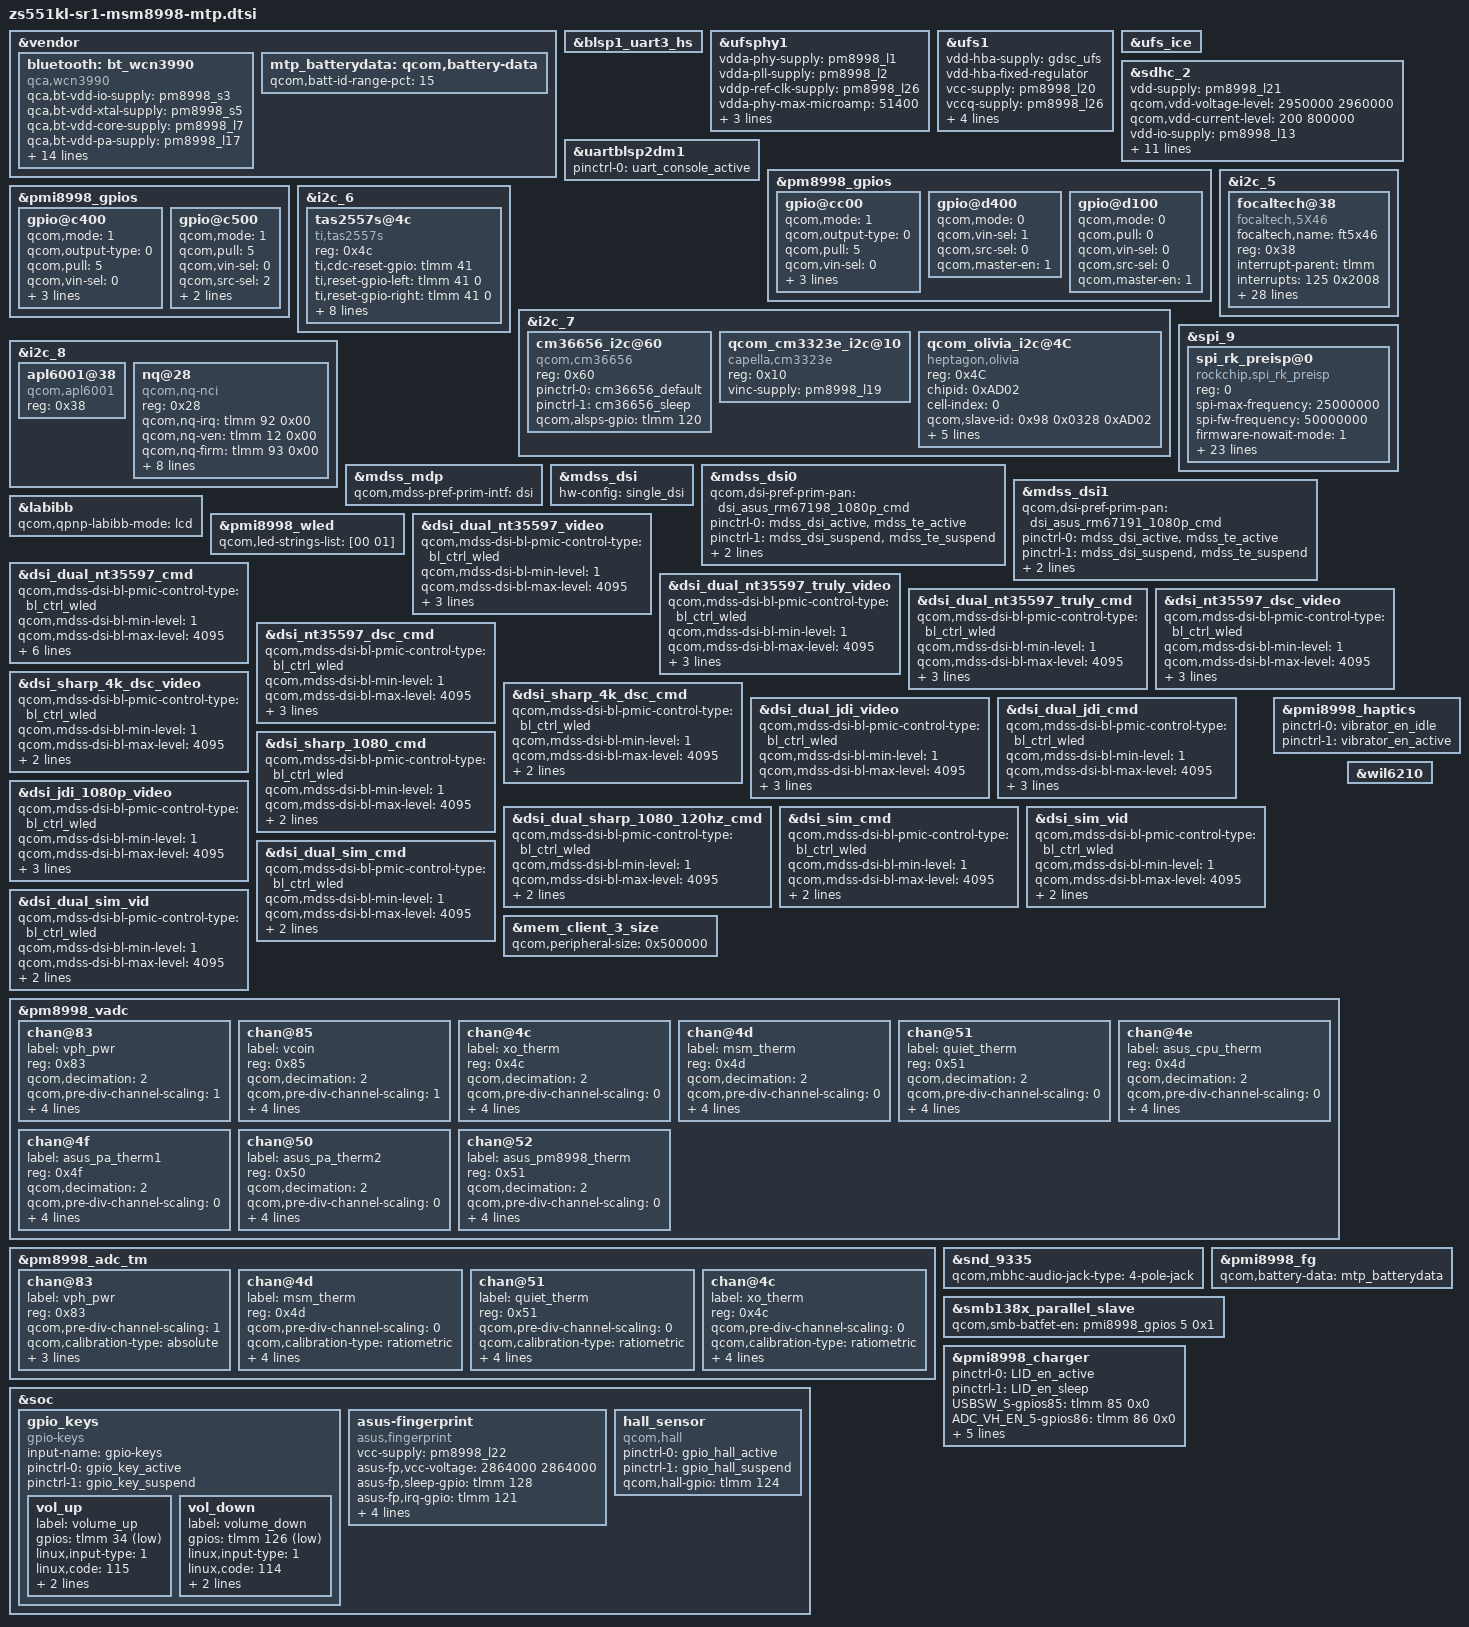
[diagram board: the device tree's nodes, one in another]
/* Copyright (c) 2016-2017, The Linux Foundation. All rights reserved.
 *
 * This program is free software; you can redistribute it and/or modify
 * it under the terms of the GNU General Public License version 2 and
 * only version 2 as published by the Free Software Foundation.
 *
 * This program is distributed in the hope that it will be useful,
 * but WITHOUT ANY WARRANTY; without even the implied warranty of
 * MERCHANTABILITY or FITNESS FOR A PARTICULAR PURPOSE.  See the
 * GNU General Public License for more details.
 */

#include <dt-bindings/interrupt-controller/irq.h>
#include "zs551kl-sr1-msm8998-pinctrl.dtsi"
#include "zs551kl-sr1-msm8998-camera-sensor-mtp.dtsi"
&vendor {
	bluetooth: bt_wcn3990 {
		compatible = "qca,wcn3990";
		qca,bt-vdd-io-supply = <&pm8998_s3>;
		qca,bt-vdd-xtal-supply = <&pm8998_s5>;
		qca,bt-vdd-core-supply = <&pm8998_l7>;
		qca,bt-vdd-pa-supply = <&pm8998_l17>;
		qca,bt-vdd-ldo-supply = <&pm8998_l25>;
		qca,bt-chip-pwd-supply = <&pmi8998_bob_pin1>;
		clocks = <&clock_gcc clk_rf_clk2_pin>;
		clock-names = "rf_clk2";

		qca,bt-vdd-io-voltage-level = <1352000 1352000>;
		qca,bt-vdd-xtal-voltage-level = <2040000 2040000>;
		qca,bt-vdd-core-voltage-level = <1800000 1800000>;
		qca,bt-vdd-pa-voltage-level = <1304000 1304000>;
		qca,bt-vdd-ldo-voltage-level = <3312000 3312000>;
		qca,bt-chip-pwd-voltage-level = <3600000 3600000>;

		qca,bt-vdd-io-current-level = <1>; /* LPM/PFM */
		qca,bt-vdd-xtal-current-level = <1>; /* LPM/PFM */
		qca,bt-vdd-core-current-level = <1>; /* LPM/PFM */
		qca,bt-vdd-pa-current-level = <1>; /* LPM/PFM */
		qca,bt-vdd-ldo-current-level = <1>; /* LPM/PFM */
	};
};

&blsp1_uart3_hs {
	status = "ok";
};

&ufsphy1 {
	vdda-phy-supply = <&pm8998_l1>;
	vdda-pll-supply = <&pm8998_l2>;
	vddp-ref-clk-supply = <&pm8998_l26>;
	vdda-phy-max-microamp = <51400>;
	vdda-pll-max-microamp = <14600>;
	vddp-ref-clk-max-microamp = <100>;
	vddp-ref-clk-always-on;
	status = "ok";
};

&ufs1 {
	vdd-hba-supply = <&gdsc_ufs>;
	vdd-hba-fixed-regulator;
	vcc-supply = <&pm8998_l20>;
	vccq-supply = <&pm8998_l26>;
	vccq2-supply = <&pm8998_s4>;
	vcc-max-microamp = <750000>;
	vccq-max-microamp = <560000>;
	vccq2-max-microamp = <750000>;
	status = "ok";
};

&ufs_ice {
	status = "ok";
};

&sdhc_2 {
	vdd-supply = <&pm8998_l21>;
	qcom,vdd-voltage-level = <2950000 2960000>;
	qcom,vdd-current-level = <200 800000>;

	vdd-io-supply = <&pm8998_l13>;
	qcom,vdd-io-voltage-level = <1808000 2960000>;
	qcom,vdd-io-current-level = <200 22000>;

	pinctrl-names = "active", "sleep";
	pinctrl-0 = <&sdc2_clk_on  &sdc2_cmd_on &sdc2_data_on &sdc2_cd_on>;
	pinctrl-1 = <&sdc2_clk_off &sdc2_cmd_off &sdc2_data_off &sdc2_cd_off>;

	qcom,clk-rates = <400000 20000000 25000000
				50000000 100000000 200000000>;
	qcom,bus-speed-mode = "SDR12", "SDR25", "SDR50", "DDR50", "SDR104";

	cd-gpios = <&tlmm 95 0x0>;

	status = "ok";
};

&uartblsp2dm1 {
	status = "ok";
	pinctrl-names = "default";
	pinctrl-0 = <&uart_console_active>;
};

&pm8998_gpios {
	/* GPIO 2 for Home Key */
	/*
	gpio@c100 {
		status = "okay";
		qcom,mode = <0>;
		qcom,pull = <0>;
		qcom,vin-sel = <0>;
		qcom,src-sel = <0>;
		qcom,out-strength = <1>;
	};
	*/
	/* GPIO 6 for Vol+ Key */
	/*
	gpio@c500 {
		status = "okay";
		qcom,mode = <0>;
		qcom,pull = <0>;
		qcom,vin-sel = <0>;
		qcom,src-sel = <0>;
		qcom,out-strength = <1>;
	};
	*/
	/* GPIO 7 for Snapshot Key */
	/*
	gpio@c600 {
		status = "okay";
		qcom,mode = <0>;
		qcom,pull = <0>;
		qcom,vin-sel = <0>;
		qcom,src-sel = <0>;
		qcom,out-strength = <1>;
	};
	*/
	/* GPIO 8 for Focus Key */
	/*
	gpio@c700 {
		status = "okay";
		qcom,mode = <0>;
		qcom,pull = <0>;
		qcom,vin-sel = <0>;
		qcom,src-sel = <0>;
		qcom,out-strength = <1>;
	};
	*/
	gpio@cc00 { /* GPIO 13 */
		qcom,mode = <1>;
		qcom,output-type = <0>;
		qcom,pull = <5>;
		qcom,vin-sel = <0>;
		qcom,out-strength = <1>;
		qcom,src-sel = <3>;
		qcom,master-en = <1>;
		status = "okay";
	};

	/* GPIO 21 (NFC_CLK_REQ) */
	gpio@d400 {
		qcom,mode = <0>;
		qcom,vin-sel = <1>;
		qcom,src-sel = <0>;
		qcom,master-en = <1>;
		status = "okay";
	};

	/* GPIO 18 SMB138X */
	gpio@d100 {
		qcom,mode = <0>;
		qcom,pull = <0>;
		qcom,vin-sel = <0>;
		qcom,src-sel = <0>;
		qcom,master-en = <1>;
		status = "okay";
	};
};

&pmi8998_gpios {
	/* GPIO 5 for SMB138x BATFET_EN signal */
	gpio@c400 {
		qcom,mode = <1>;
		qcom,output-type = <0>;
		qcom,pull = <5>;
		qcom,vin-sel = <0>;
		qcom,out-strength = <1>;
		qcom,src-sel = <3>;
		qcom,master-en = <1>;
		status = "okay";
	};

	/* GPIO 6 for the internal QNOVO discharge FET control signal */
	gpio@c500 {
		status = "okay";
		qcom,mode = <1>;
		qcom,pull = <5>;
		qcom,vin-sel = <0>;
		qcom,src-sel = <2>;
		qcom,out-strength = <1>;
		qcom,master-en = <1>;
	};
};

//+++.....................................................Peripheral bus part....................................................+++//
 
&i2c_5 {	/* BLSP5 (BLSP QUP5) for Touch */
	status = "okay";
	focaltech@38 {
		compatible = "focaltech,5X46";
		focaltech,name = "ft5x46";
		reg = <0x38>;
		interrupt-parent = <&tlmm>;
		interrupts = <125 0x2008>;
		vdd-supply = <&pm8998_l28>;
		vcc_i2c-supply = <&pm8998_l14>;
		/* pins used by touchscreen */
		/*pinctrl-names = "pmx_ts_active","pmx_ts_suspend","pmx_ts_release";
		pinctrl-0 = <&ts_int_active &ts_reset_active>;
		pinctrl-1 = <&ts_int_suspend &ts_reset_suspend>;
		pinctrl-2 = <&ts_release>;*/
		focaltech,family-id = <0x36>;
		focaltech,reset-gpio = <&tlmm 89 0x0>;
		focaltech,irq-gpio = <&tlmm 125 0x2008>;
		/*focaltech,tpid1-gpio=<&tlmm 140 0x0>;
		focaltech,tpid0-gpio=<&tlmm 67 0x0>;*/
		/*focaltech,lcdid0-gpio=<&tlmm 59 0x0>;
		focaltech,lcdid1-gpio=<&tlmm 62 0x0>;*/
		focaltech,display-coords = <0 0 1080 1920>;
		focaltech,panel-coords = <0 0 1080 1920>;
		focaltech,button-map= <139 102 158>;
		focaltech,have-key;
		focaltech,key-number = <3>;
		focaltech,max-touch-number = <10>;
		focaltech,keys = <158 102 139>;
		focaltech,key-y-coord = <2000>;
		focaltech,key-x-coord = <200 400 600>;

		focaltech,no-force-update;
		focaltech,i2c-pull-up;
		focaltech,group-id = <1>;
		focaltech,hard-reset-delay-ms = <20>;
		focaltech,soft-reset-delay-ms = <200>;
		focaltech,num-max-touches = <5>;
		focaltech,fw-delay-aa-ms = <30>;
		focaltech,fw-delay-55-ms = <30>;
		focaltech,fw-upgrade-id1 = <0x79>;
		focaltech,fw-upgrade-id2 = <0x18>;
		focaltech,fw-delay-readid-ms = <10>;
		focaltech,fw-delay-era-flsh-ms = <2000>;
		focaltech,fw-auto-cal;
		focaltech,ignore-id-check;

	};
};

&i2c_6 {	/* BLSP6 (BLSP QUP6) for Audio */
	status = "okay";
	tas2557s@4c {
		compatible = "ti,tas2557s";
		reg = <0x4c>;
		ti,cdc-reset-gpio = <&tlmm 41 0>;
		ti,reset-gpio-left = <&tlmm 41 0>;
		ti,reset-gpio-right = <&tlmm 41 0>;
		ti,load = <0>;   /* 0, 8Ohm; 1, 6Ohm; 2, 4Ohm */
		ti,irq-gpio-left = <&tlmm 76 0>;
		ti,irq-gpio-right = <&tlmm 75 0>;
		ti,left-channel = <0x4d>;
		ti,right-channel = <0x4c>;
		ti,echo-ref = <0>;   /* 0, left channel; 1, right channel; 2, both */
		ti,i2s-bits = <24>;  /* support 16, 24, 32 */
		ti,bypass-tmax = <0>;   /* 0, not bypass; 1, bypass */
	};
};

&i2c_7 {	/* BLSP7 (BLSP QUP7) for Sensors */
	status = "okay";

	/* ASUS_BSP +++ ShawnHuang CM36656 */
	cm36656_i2c@60 {
		compatible = "qcom,cm36656";
		reg = <0x60>;
		pinctrl-names = "alsps_gpio_high","alsps_gpio_low";
		pinctrl-0 = <&cm36656_default>;
		pinctrl-1 = <&cm36656_sleep>;
		qcom,alsps-gpio = <&tlmm 120 0x0>;
	};
	/* ASUS_BSP --- ShawnHuang CM36656 */

	/* ASUS_BSP: Vincent: rgb sensor i2c ++*/
	qcom_cm3323e_i2c@10 {
		compatible = "capella,cm3323e";
		reg = <0x10>;
		vinc-supply=<&pm8998_l19>;
	};		
	/* ASUS_BSP: Vincent: rgb sensor i2c --*/

	/* ASUS_BSP: Vincent: Laser sensor i2c ++*/
	qcom_olivia_i2c@4C {
		compatible = "heptagon,olivia";
		reg = <0x4C>;		
		chipid = <0xAD02>;
		cell-index = <0>;
		qcom,slave-id = <0x98 0x0328 0xAD02>;
		label = "Olivia";
		vinc-supply=<&pm8998_l19>;
		qcom,elisa-gpio = <&tlmm 117 0x0>;
		pinctrl-names = "laser_gpio_high","laser_gpio_low";
		pinctrl-0 = <&laser_default>;
		pinctrl-1 = <&laser_sleep>;		
	};
	/* ASUS_BSP: Vincent: Laser sensor i2c --*/	
};

&i2c_8 {	/* BLSP8(BLSP2 QUP2) for Audio, Buttery, Power */
	status = "okay";

	apl6001@38 {
		compatible = "qcom,apl6001";
		reg = <0x38>;
		#address-cells = <1>;
		#size-cells = <0>;
	};

	nq@28 {
		compatible = "qcom,nq-nci";
		reg = <0x28>;
		qcom,nq-irq = <&tlmm 92 0x00>;
		qcom,nq-ven = <&tlmm 12 0x00>;
		qcom,nq-firm = <&tlmm 93 0x00>;
		qcom,nq-clkreq = <&pm8998_gpios 21 0x00>;
		qcom,nq-esepwr = <&tlmm 116 0x00>;
		interrupt-parent = <&tlmm>;
		qcom,clk-src = "BBCLK3";
		interrupts = <92 0>;
		interrupt-names = "nfc_irq";
		pinctrl-names = "nfc_active", "nfc_suspend";
		pinctrl-0 = <&nfc_int_active &nfc_enable_active>;
		pinctrl-1 = <&nfc_int_suspend &nfc_enable_suspend>;
		clocks = <&clock_gcc clk_ln_bb_clk3_pin>;
		clock-names = "ref_clk";
	};

};

// ASUS_BSP Deka +++ "Bring up Pre-ISP RK1608"
&spi_9 {	/* BLSP9 (BLSP QUP9) for SPI RK1608 */
	status = "okay";
	spi_rk_preisp@0 {
		compatible =  "rockchip,spi_rk_preisp";
		reg = <0>;
		spi-max-frequency = <25000000>;
		spi-fw-frequency = <50000000>; /* 2 times spi-max-frequency*/
		firmware-nowait-mode = <1>;
		irq-gpio = <&tlmm 9 0>;
		reset-gpio = <&tlmm 23 0>;
		sleepst-gpio=<&tlmm 26 0>;
		wakeup-gpio = <&tlmm 8 0>;
		snapshot-gpio=<&tlmm 100 0>;
		en1v0-gpio = <&pm8998_gpios 20 0>;
		core_vdd-supply=<&pm8998_lvs1>;
		qcom,cam-vreg-name = "core_vdd";
		qcom,cam-vreg-min-voltage = <0>;
		qcom,cam-vreg-max-voltage = <0>;
		qcom,cam-vreg-op-mode = <0>;
		pinctrl-names = "cam_default", "cam_suspend";
		pinctrl-0 = <&preisp_mclk_default &preisp_irq_gpios_default &preisp_gpios_default>;
		pinctrl-1 = <&preisp_mclk_sleep &preisp_irq_gpios_sleep &preisp_gpios_sleep>;
		gpios=<&tlmm 16 0>;
		qcom,gpio-req-tbl-num = <0 >;
		qcom,gpio-req-tbl-flags = <1 >;
		qcom,gpio-req-tbl-label = "CAMIF_MCLK3";
		clocks = <&clock_mmss clk_mclk3_clk_src>,<&clock_mmss clk_mmss_camss_mclk3_clk>;
		clock-names = "cam_src_clk", "cam_clk";
		qcom,clock-rates = <19200000 0>;
	};
};
// ASUS_BSP Deka --- "Bring up Pre-ISP RK1608"


//---.....................................................Peripheral bus part....................................................---//
// ASUS_BSP Remove HDMI HDP +++
/*

&mdss_hdmi_tx {
	pinctrl-names = "hdmi_hpd_active", "hdmi_ddc_active", "hdmi_cec_active",
				"hdmi_active", "hdmi_sleep";
	pinctrl-0 = <&mdss_hdmi_5v_active  &mdss_hdmi_hpd_active
			&mdss_hdmi_ddc_suspend &mdss_hdmi_cec_suspend>;
	pinctrl-1 = <&mdss_hdmi_5v_active &mdss_hdmi_hpd_active
			&mdss_hdmi_ddc_active &mdss_hdmi_cec_suspend>;
	pinctrl-2 = <&mdss_hdmi_5v_active &mdss_hdmi_hpd_active
			&mdss_hdmi_cec_active &mdss_hdmi_ddc_suspend>;
	pinctrl-3 = <&mdss_hdmi_5v_active &mdss_hdmi_hpd_active
			&mdss_hdmi_ddc_active &mdss_hdmi_cec_active>;
	pinctrl-4 = <&mdss_hdmi_5v_suspend &mdss_hdmi_hpd_suspend
			&mdss_hdmi_ddc_suspend &mdss_hdmi_cec_suspend>;
};
*/
// ASUS_BSP Remove HDMI HDP ---

// ASUS BSP Display, disable DP +++
/*
&mdss_dp_ctrl {
	pinctrl-names = "mdss_dp_active", "mdss_dp_sleep";
	pinctrl-0 = <&mdss_dp_aux_active &mdss_dp_usbplug_cc_active>;
	pinctrl-1 = <&mdss_dp_aux_suspend &mdss_dp_usbplug_cc_suspend>;
	qcom,aux-en-gpio = <&tlmm 77 0>;
	qcom,aux-sel-gpio = <&tlmm 78 0>;
	qcom,usbplug-cc-gpio = <&tlmm 38 0>;
};
*/
// ASUS BSP Display, disable DP ---

&mdss_mdp {
	qcom,mdss-pref-prim-intf = "dsi";
};

&mdss_dsi {
	hw-config = "single_dsi";
};

&mdss_dsi0 {
	qcom,dsi-pref-prim-pan = <&dsi_asus_rm67198_1080p_cmd>;
	pinctrl-names = "mdss_default", "mdss_sleep";
	pinctrl-0 = <&mdss_dsi_active &mdss_te_active>;
	pinctrl-1 = <&mdss_dsi_suspend &mdss_te_suspend>;
	qcom,platform-reset-gpio = <&tlmm 94 0>;
	qcom,platform-te-gpio = <&tlmm 10 0>;
};

&mdss_dsi1 {
	qcom,dsi-pref-prim-pan = <&dsi_asus_rm67191_1080p_cmd>;
	pinctrl-names = "mdss_default", "mdss_sleep";
	pinctrl-0 = <&mdss_dsi_active &mdss_te_active>;
	pinctrl-1 = <&mdss_dsi_suspend &mdss_te_suspend>;
	qcom,platform-reset-gpio = <&tlmm 94 0>;
	qcom,platform-te-gpio = <&tlmm 10 0>;
};

&labibb {
	status = "ok";
	qcom,qpnp-labibb-mode = "lcd";
};

&pmi8998_wled {
	qcom,led-strings-list = [00 01];
};

&dsi_dual_nt35597_video {
	qcom,mdss-dsi-bl-pmic-control-type = "bl_ctrl_wled";
	qcom,mdss-dsi-bl-min-level = <1>;
	qcom,mdss-dsi-bl-max-level = <4095>;
	qcom,mdss-dsi-mode-sel-gpio-state = "dual_port";
	qcom,panel-supply-entries = <&dsi_panel_pwr_supply>;
};

&dsi_dual_nt35597_cmd {
	qcom,mdss-dsi-bl-pmic-control-type = "bl_ctrl_wled";
	qcom,mdss-dsi-bl-min-level = <1>;
	qcom,mdss-dsi-bl-max-level = <4095>;
	qcom,mdss-dsi-mode-sel-gpio-state = "dual_port";
	qcom,panel-supply-entries = <&dsi_panel_pwr_supply>;
	qcom,partial-update-enabled = "single_roi";
	qcom,panel-roi-alignment = <720 256 720 256 1440 256>;
};

&dsi_dual_nt35597_truly_video {
	qcom,mdss-dsi-bl-pmic-control-type = "bl_ctrl_wled";
	qcom,mdss-dsi-bl-min-level = <1>;
	qcom,mdss-dsi-bl-max-level = <4095>;
	qcom,mdss-dsi-mode-sel-gpio-state = "dual_port";
	qcom,panel-supply-entries = <&dsi_panel_pwr_supply>;
};

&dsi_dual_nt35597_truly_cmd {
	qcom,mdss-dsi-bl-pmic-control-type = "bl_ctrl_wled";
	qcom,mdss-dsi-bl-min-level = <1>;
	qcom,mdss-dsi-bl-max-level = <4095>;
	qcom,mdss-dsi-mode-sel-gpio-state = "dual_port";
	qcom,panel-supply-entries = <&dsi_panel_pwr_supply>;
};

&dsi_nt35597_dsc_video {
	qcom,mdss-dsi-bl-pmic-control-type = "bl_ctrl_wled";
	qcom,mdss-dsi-bl-min-level = <1>;
	qcom,mdss-dsi-bl-max-level = <4095>;
	qcom,mdss-dsi-mode-sel-gpio-state = "single_port";
	qcom,panel-supply-entries = <&dsi_panel_pwr_supply>;
};

&dsi_nt35597_dsc_cmd {
	qcom,mdss-dsi-bl-pmic-control-type = "bl_ctrl_wled";
	qcom,mdss-dsi-bl-min-level = <1>;
	qcom,mdss-dsi-bl-max-level = <4095>;
	qcom,mdss-dsi-mode-sel-gpio-state = "single_port";
	qcom,panel-supply-entries = <&dsi_panel_pwr_supply>;
};

&dsi_sharp_4k_dsc_video {
	qcom,mdss-dsi-bl-pmic-control-type = "bl_ctrl_wled";
	qcom,mdss-dsi-bl-min-level = <1>;
	qcom,mdss-dsi-bl-max-level = <4095>;
	qcom,panel-supply-entries = <&dsi_panel_pwr_supply>;
};

&dsi_sharp_4k_dsc_cmd {
	qcom,mdss-dsi-bl-pmic-control-type = "bl_ctrl_wled";
	qcom,mdss-dsi-bl-min-level = <1>;
	qcom,mdss-dsi-bl-max-level = <4095>;
	qcom,panel-supply-entries = <&dsi_panel_pwr_supply>;
};

&dsi_dual_jdi_video {
	qcom,mdss-dsi-bl-pmic-control-type = "bl_ctrl_wled";
	qcom,mdss-dsi-bl-min-level = <1>;
	qcom,mdss-dsi-bl-max-level = <4095>;
	qcom,5v-boost-gpio = <&tlmm 51 0>;
	qcom,panel-supply-entries = <&dsi_panel_pwr_supply>;
};

&dsi_dual_jdi_cmd {
	qcom,mdss-dsi-bl-pmic-control-type = "bl_ctrl_wled";
	qcom,mdss-dsi-bl-min-level = <1>;
	qcom,mdss-dsi-bl-max-level = <4095>;
	qcom,5v-boost-gpio = <&tlmm 51 0>;
	qcom,panel-supply-entries = <&dsi_panel_pwr_supply>;
};

&dsi_sharp_1080_cmd {
	qcom,mdss-dsi-bl-pmic-control-type = "bl_ctrl_wled";
	qcom,mdss-dsi-bl-min-level = <1>;
	qcom,mdss-dsi-bl-max-level = <4095>;
	qcom,panel-supply-entries = <&dsi_panel_pwr_supply>;
};

&dsi_jdi_1080p_video {
	qcom,mdss-dsi-bl-pmic-control-type = "bl_ctrl_wled";
	qcom,mdss-dsi-bl-min-level = <1>;
	qcom,mdss-dsi-bl-max-level = <4095>;
	qcom,panel-supply-entries = <&dsi_panel_pwr_supply_no_labibb>;
	qcom,5v-boost-gpio = <&tlmm 51 0>;
};

&dsi_dual_sharp_1080_120hz_cmd {
	qcom,mdss-dsi-bl-pmic-control-type = "bl_ctrl_wled";
	qcom,mdss-dsi-bl-min-level = <1>;
	qcom,mdss-dsi-bl-max-level = <4095>;
	qcom,panel-supply-entries = <&dsi_panel_pwr_supply>;
};

&dsi_sim_cmd {
	qcom,mdss-dsi-bl-pmic-control-type = "bl_ctrl_wled";
	qcom,mdss-dsi-bl-min-level = <1>;
	qcom,mdss-dsi-bl-max-level = <4095>;
	qcom,panel-supply-entries = <&dsi_panel_pwr_supply>;
};

&dsi_sim_vid {
	qcom,mdss-dsi-bl-pmic-control-type = "bl_ctrl_wled";
	qcom,mdss-dsi-bl-min-level = <1>;
	qcom,mdss-dsi-bl-max-level = <4095>;
	qcom,panel-supply-entries = <&dsi_panel_pwr_supply>;
};

&dsi_dual_sim_cmd {
	qcom,mdss-dsi-bl-pmic-control-type = "bl_ctrl_wled";
	qcom,mdss-dsi-bl-min-level = <1>;
	qcom,mdss-dsi-bl-max-level = <4095>;
	qcom,panel-supply-entries = <&dsi_panel_pwr_supply>;
};

&dsi_dual_sim_vid {
	qcom,mdss-dsi-bl-pmic-control-type = "bl_ctrl_wled";
	qcom,mdss-dsi-bl-min-level = <1>;
	qcom,mdss-dsi-bl-max-level = <4095>;
	qcom,panel-supply-entries = <&dsi_panel_pwr_supply>;
};

&mem_client_3_size {
	qcom,peripheral-size = <0x500000>;
};

&pmi8998_haptics {
	status = "okay";
};

&pm8998_vadc {
	chan@83 {
		label = "vph_pwr";
		reg = <0x83>;
		qcom,decimation = <2>;
		qcom,pre-div-channel-scaling = <1>;
		qcom,calibration-type = "absolute";
		qcom,scale-function = <0>;
		qcom,hw-settle-time = <0>;
		qcom,fast-avg-setup = <0>;
	};

	chan@85 {
		label = "vcoin";
		reg = <0x85>;
		qcom,decimation = <2>;
		qcom,pre-div-channel-scaling = <1>;
		qcom,calibration-type = "absolute";
		qcom,scale-function = <0>;
		qcom,hw-settle-time = <0>;
		qcom,fast-avg-setup = <0>;
	};

	chan@4c {
		label = "xo_therm";
		reg = <0x4c>;
		qcom,decimation = <2>;
		qcom,pre-div-channel-scaling = <0>;
		qcom,calibration-type = "ratiometric";
		qcom,scale-function = <4>;
		qcom,hw-settle-time = <2>;
		qcom,fast-avg-setup = <0>;
	};

	chan@4d {
		label = "msm_therm";
		reg = <0x4d>;
		qcom,decimation = <2>;
		qcom,pre-div-channel-scaling = <0>;
		qcom,calibration-type = "ratiometric";
		qcom,scale-function = <2>;
		qcom,hw-settle-time = <2>;
		qcom,fast-avg-setup = <0>;
	};

	chan@51 {
		label = "quiet_therm";
		reg = <0x51>;
		qcom,decimation = <2>;
		qcom,pre-div-channel-scaling = <0>;
		qcom,calibration-type = "ratiometric";
		qcom,scale-function = <2>;
		qcom,hw-settle-time = <2>;
		qcom,fast-avg-setup = <0>;
	};
	
	/* ASUS_BSP (ShowCai) +++ for thermal */
	chan@4e {
		label = "asus_cpu_therm";
		reg = <0x4d>;
		qcom,decimation = <2>;
		qcom,pre-div-channel-scaling = <0>;
		qcom,calibration-type = "ratiometric";
		qcom,scale-function = <2>;
		qcom,hw-settle-time = <2>;
		qcom,fast-avg-setup = <0>;
	};
	
	chan@4f {
		label = "asus_pa_therm1";
		reg = <0x4f>;
		qcom,decimation = <2>;
		qcom,pre-div-channel-scaling = <0>;
		qcom,calibration-type = "ratiometric";
		qcom,scale-function = <2>;
		qcom,hw-settle-time = <2>;
		qcom,fast-avg-setup = <0>;
	};
	
	chan@50 {
		label = "asus_pa_therm2";
		reg = <0x50>;
		qcom,decimation = <2>;
		qcom,pre-div-channel-scaling = <0>;
		qcom,calibration-type = "ratiometric";
		qcom,scale-function = <2>;
		qcom,hw-settle-time = <2>;
		qcom,fast-avg-setup = <0>;
	};
	
	chan@52 {
		label = "asus_pm8998_therm";
		reg = <0x51>;
		qcom,decimation = <2>;
		qcom,pre-div-channel-scaling = <0>;
		qcom,calibration-type = "ratiometric";
		qcom,scale-function = <2>;
		qcom,hw-settle-time = <2>;
		qcom,fast-avg-setup = <0>;
	};
	/* ASUS_BSP (ShowCai) --- for thermal */
};

&pm8998_adc_tm {
	chan@83 {
		label = "vph_pwr";
		reg = <0x83>;
		qcom,pre-div-channel-scaling = <1>;
		qcom,calibration-type = "absolute";
		qcom,scale-function = <0>;
		qcom,hw-settle-time = <0>;
		qcom,btm-channel-number = <0x60>;
	};

	chan@4d {
		label = "msm_therm";
		reg = <0x4d>;
		qcom,pre-div-channel-scaling = <0>;
		qcom,calibration-type = "ratiometric";
		qcom,scale-function = <2>;
		qcom,hw-settle-time = <2>;
		qcom,btm-channel-number = <0x68>;
		qcom,thermal-node;
	};

	chan@51 {
		label = "quiet_therm";
		reg = <0x51>;
		qcom,pre-div-channel-scaling = <0>;
		qcom,calibration-type = "ratiometric";
		qcom,scale-function = <2>;
		qcom,hw-settle-time = <2>;
		qcom,btm-channel-number = <0x70>;
		qcom,thermal-node;
	};

	chan@4c {
		label = "xo_therm";
		reg = <0x4c>;
		qcom,pre-div-channel-scaling = <0>;
		qcom,calibration-type = "ratiometric";
		qcom,scale-function = <4>;
		qcom,hw-settle-time = <2>;
		qcom,btm-channel-number = <0x78>;
		qcom,thermal-node;
	};
};

&wil6210 {
	status = "ok";
};

&snd_9335 {
	qcom,mbhc-audio-jack-type = "4-pole-jack";
};

&soc {
	gpio_keys {
		compatible = "gpio-keys";
		input-name = "gpio-keys";
		status = "okay";
		/*  ASUS_BSP Freddy ++++  */
		pinctrl-names = "tlmm_gpio_key_active","tlmm_gpio_key_suspend";
		pinctrl-0 = <&gpio_key_active>;
		pinctrl-1 = <&gpio_key_suspend>;
		vol_up {
				label = "volume_up";
				gpios = <&tlmm 34 0x1>;
				linux,input-type = <1>;
				linux,code = <115>;
				gpio-key,wakeup;
				debounce-interval = <15>;
		};
		vol_down {
				label = "volume_down";
				gpios = <&tlmm 126 0x1>;
				linux,input-type = <1>;
				linux,code = <114>;
				gpio-key,wakeup;
				debounce-interval = <15>;
		};
	};

	// ASUS_BSP +++ Jacob Fingerprint sensor
	asus-fingerprint {
		compatible = "asus,fingerprint";
		vcc-supply = <&pm8998_l22>;
		asus-fp,vcc-voltage = <2864000 2864000>;
		asus-fp,sleep-gpio = <&tlmm 128 0x0>;
		asus-fp,irq-gpio = <&tlmm 121 0x2008>;
		asus-fp,ID1-gpio = <&tlmm 99 0x0>;
//		asus-fp,vcc-enable-Leo-gpio = <&tlmm 40 0x0>;
//		asus-fp,vcc-enable-Libra-gpio = <&tlmm 87 0x0>;
//		asus-fp,ID1-gpio = <&tlmm 141 0x0>;
//		asus-fp,ID2-gpio = <&tlmm 66 0x0>;

		/* Pinctrl Setting */
		qcom,use-pinctrl;
		pinctrl-names = "fp_default", "fp_sleep";
		pinctrl-0 = <&fp_int_active>;
		pinctrl-1 = <&fp_int_suspend>;
	};
	// ASUS_BSP --- Jacob Fingerprint sensor

	// ASUS_BSP +++ ShawnHuang HALL sensor
	hall_sensor {
		compatible = "qcom,hall";
		pinctrl-names = "hall_gpio_high","hall_gpio_low";
		pinctrl-0 = <&gpio_hall_active>;
		pinctrl-1 = <&gpio_hall_suspend>;			
		qcom,hall-gpio = <&tlmm 124 0x0>;
	};
	// ASUS_BSP --- ShawnHuang HALL sensor
};

&vendor {
	mtp_batterydata: qcom,battery-data {
		qcom,batt-id-range-pct = <15>;
		#include "fg-gen3-batterydata-3400mah_4p25V.dtsi"
		#include "fg-gen3-batterydata-3400mah_4p3V.dtsi"
		#include "fg-gen3-batterydata-3400mah_4p35V.dtsi"
	};
};

&pmi8998_fg {
	qcom,battery-data = <&mtp_batterydata>;
};

&smb138x_parallel_slave {
	qcom,smb-batfet-en = <&pmi8998_gpios 5 0x1>;
};

//ASUS BSP : Austin_Tsneg Charger +++
&pmi8998_charger {
	pinctrl-0 = <&LID_en_active>;
	pinctrl-1 = <&LID_en_sleep>;
	USBSW_S-gpios85 = <&tlmm 85 0x0>;
	ADC_VH_EN_5-gpios86 = <&tlmm 86 0x0>;
	USB_THERMAL_ALERT-gpios79 = <&tlmm 79 0x0>;
	USB_LOW_IMPEDANCE-gpios63 = <&tlmm 63 0x0>;
	USB_LID_EN-gpios62 = <&tlmm 62 0x0>;
	USB_WATER_PROOF-gpios77 = <&tlmm 77 0x0>;
	PW_ADC_EN-gpios90 = <&tlmm 90 0x0>;
};
//ASUS BSP : Austin_Tseng Charger ---

//ASUS_BSP_Vibrator +++, AMP enable pin, gpio 60, mark_guo
&pmi8998_haptics {
	pinctrl-0 = <&vibrator_en_idle>;
	pinctrl-1 = <&vibrator_en_active>;
};
//ASUS_BSP_Vibrator ---

